# RP2350 register map
Vendor: Raspberry Pi; Series: RP; File version: 0.1
CPU: CM33 r1p0, little endian, MPU, FPU, DSP, VTOR, 4 interrupt priority bits, 52 interrupts, 8 SAU regions
Registers are 32-bit, read-write, reset 0x0 unless marked. A register's access mark holds for its fields unless they carry their own. Offsets are from the block's base; [hi:lo] are bit positions; lines under a group give offsets from that group; {n}, {i} and the like mark numbered series; 'fields as' and 'values as' point back to an identical list; <NAME> marks a mode.

## PADS_BANK0
Base 0x40038000
0x00 VOLTAGE_SELECT — Voltage select. Per bank control
  [0] VOLTAGE_SELECT
    0=3v3 (Set voltage to 3.3V (DVDD >= 2V5)); 1=1v8 (Set voltage to 1.8V (DVDD <= 1V8))
{0x4+4i} GPIO[{i}] (i=0..47) group
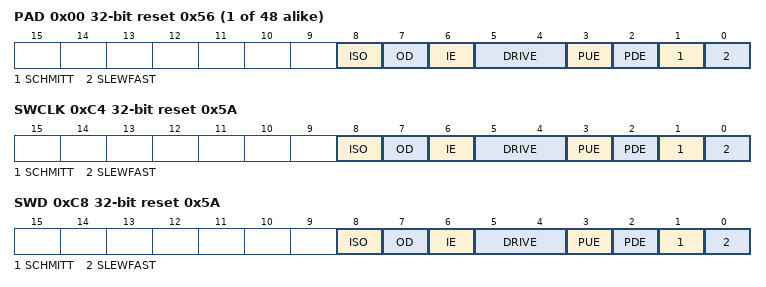
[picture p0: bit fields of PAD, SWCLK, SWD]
  0x00 PAD reset 0x56 — Pad control register
    [8] ISO — Pad isolation control. Remove this once the pad is configured by software.
    [7] OD — Output disable. Has priority over output enable from peripherals
    [6] IE — Input enable
    [5:4] DRIVE — Drive strength.
      0=2mA; 1=4mA; 2=8mA; 3=12mA
    [3] PUE — Pull up enable
    [2] PDE — Pull down enable
    [1] SCHMITT — Enable schmitt trigger
    [0] SLEWFAST — Slew rate control. 1 = Fast, 0 = Slow
0xC4 SWCLK reset 0x5A
  fields as GPIO[0].PAD
0xC8 SWD reset 0x5A
  fields as GPIO[0].PAD

## PADS_QSPI
Base 0x40040000
0x00 VOLTAGE_SELECT — Voltage select. Per bank control
  [0] VOLTAGE_SELECT
    0=3v3 (Set voltage to 3.3V (DVDD >= 2V5)); 1=1v8 (Set voltage to 1.8V (DVDD <= 1V8))
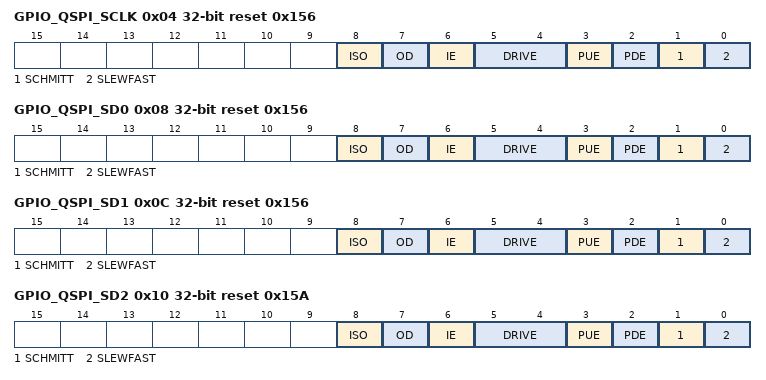
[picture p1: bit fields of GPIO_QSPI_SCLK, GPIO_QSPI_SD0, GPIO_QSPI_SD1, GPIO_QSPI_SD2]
0x04 GPIO_QSPI_SCLK reset 0x156
  [8] ISO — Pad isolation control. Remove this once the pad is configured by software.
  [7] OD — Output disable. Has priority over output enable from peripherals
  [6] IE — Input enable
  [5:4] DRIVE — Drive strength.
    0=2mA; 1=4mA; 2=8mA; 3=12mA
  [3] PUE — Pull up enable
  [2] PDE — Pull down enable
  [1] SCHMITT — Enable schmitt trigger
  [0] SLEWFAST — Slew rate control. 1 = Fast, 0 = Slow
0x08 GPIO_QSPI_SD0 reset 0x156
  fields as GPIO_QSPI_SCLK
0x0C GPIO_QSPI_SD1 reset 0x156
  fields as GPIO_QSPI_SCLK
0x10 GPIO_QSPI_SD2 reset 0x15A
  fields as GPIO_QSPI_SCLK
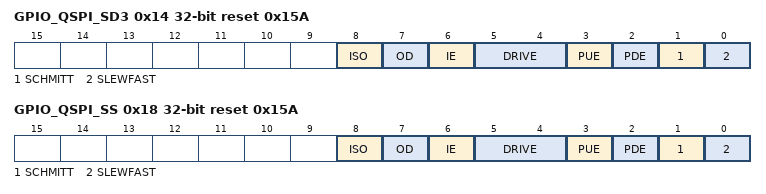
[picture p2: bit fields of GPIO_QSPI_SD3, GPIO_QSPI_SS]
0x14 GPIO_QSPI_SD3 reset 0x15A
  fields as GPIO_QSPI_SCLK
0x18 GPIO_QSPI_SS reset 0x15A
  fields as GPIO_QSPI_SCLK

## SYSINFO
Base 0x40000000
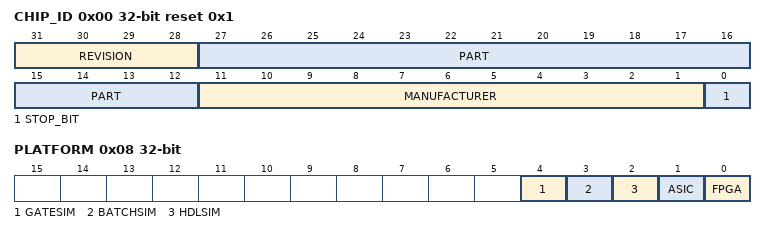
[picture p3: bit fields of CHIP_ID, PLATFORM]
0x00 CHIP_ID reset 0x1 — JEDEC JEP-106 compliant chip identifier.
  [31:28] REVISION ro, [27:12] PART ro, [11:1] MANUFACTURER ro, [0] STOP_BIT ro
0x04 PACKAGE_SEL
  [0] PACKAGE_SEL ro
0x08 PLATFORM — Platform register. Allows software to know what environment it is running in during pre-production development. Post-production, the PLATFORM is always ASIC, non-SIM.
  [4] GATESIM ro, [3] BATCHSIM ro, [2] HDLSIM ro, [1] ASIC ro, [0] FPGA ro
0x14 GITREF_RP2350 reset not defined — Git hash of the chip source. Used to identify chip version.
  [31:0] GITREF_RP2350 ro

## SHA256 — SHA-256 hash function implementation
Base 0x400F8000
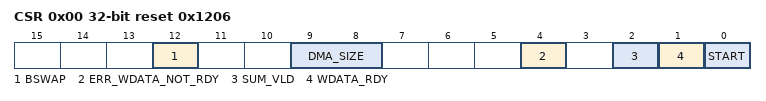
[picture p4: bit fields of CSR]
0x00 CSR reset 0x1206 — Control and status register
  [12] BSWAP — Enable byte swapping of 32-bit values at the point they are committed to the SHA message scheduler. This block's bus interface assembles byte/halfword data into message words in little-endian order, so that DMAing the same buffer with different transfer sizes always gives the same result on a little-endian system like RP2350. However, when marshalling bytes into blocks, SHA expects that the first byte is the *most significant* in each message word. To resolve this, once the bus interface has accumulated 32 bits of data (either a word write, two halfword writes in little-endian order, or four byte writes in little-endian order) the final value can be byte-swapped before passing to the actual SHA core. This feature is enabled by default because using the SHA core to checksum byte buffers is expected to be more common than having preformatted SHA message words lying around.
  [9:8] DMA_SIZE — Configure DREQ logic for the correct DMA data size. Must be configured before the DMA channel is triggered. The SHA-256 core's DREQ logic requests one entire block of data at once, since there is no FIFO, and data goes straight into the core's message schedule and digest hardware. Therefore, when transferring data with DMA, CSR_DMA_SIZE must be configured in advance so that the correct number of transfers can be requested per block.
    0=8bit; 1=16bit; 2=32bit
  [4] ERR_WDATA_NOT_RDY write-1-clears — Set when a write occurs whilst the SHA-256 core is not ready for data (WDATA_RDY is low). Write one to clear.
  [2] SUM_VLD ro — If 1, the SHA-256 checksum presented in registers SUM0 through SUM7 is currently valid. Goes low when WDATA is first written, then returns high once 16 words have been written and the digest of the current 512-bit block has subsequently completed.
  [1] WDATA_RDY ro — If 1, the SHA-256 core is ready to accept more data through the WDATA register. After writing 16 words, this flag will go low for 57 cycles whilst the core completes its digest.
  [0] START wo write-1-sets — Write 1 to prepare the SHA-256 core for a new checksum. The SUMx registers are initialised to the proper values (fractional bits of square roots of first 8 primes) and internal counters are cleared. This immediately forces WDATA_RDY and SUM_VLD high. START must be written before initiating a DMA transfer to the SHA-256 core, because the core will always request 16 transfers at a time (1 512-bit block). Additionally, the DMA channel should be configured for a multiple of 16 32-bit transfers.
0x04 WDATA — Write data register
  [31:0] WDATA wo — After pulsing START and writing 16 words of data to this register, WDATA_RDY will go low and the SHA-256 core will complete the digest of the current 512-bit block. Software is responsible for ensuring the data is correctly padded and terminated to a whole number of 512-bit blocks. After this, WDATA_RDY will return high, and more data can be written (if any). This register supports word, halfword and byte writes, so that DMA from non-word-aligned buffers can be supported. The total amount of data per block remains the same (16 words, 32 halfwords or 64 bytes) and byte/halfword transfers must not be mixed within a block.
{0x8+4i} SUM{i} (i=0..7) — 256-bit checksum result. Contents are undefined when CSR_SUM_VLD is 0.
  [31:0] SUM{i} ro
